# ENCODER0_REG_TOPAZHP_COREEXT_0 register map
Vendor: Texas Instruments
Peripheral module from a debugger description file (folder J7ES).
Registers are 32-bit, read-write, reset 0x0 unless marked. A register's access mark holds for its fields unless they carry their own. Offsets are as the file gives them; lines under a group give offsets from that group; [hi:lo] are bit positions; {n}, {i} and the like mark numbered series; 'fields as' and 'values as' point back to an identical list; <NAME> marks a mode.

## ENCODER0_REG_TOPAZHP_COREEXT_0
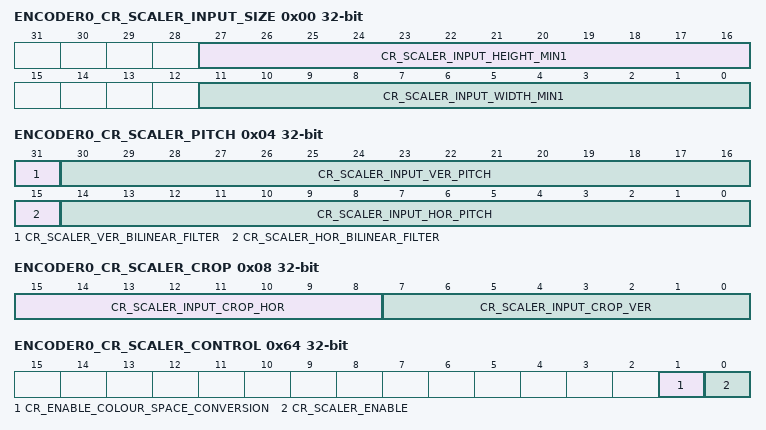
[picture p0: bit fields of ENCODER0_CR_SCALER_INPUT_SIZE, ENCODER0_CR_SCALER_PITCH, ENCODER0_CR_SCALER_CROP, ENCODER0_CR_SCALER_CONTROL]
0x00 ENCODER0_CR_SCALER_INPUT_SIZE access per field
  [27:16] CR_SCALER_INPUT_HEIGHT_MIN1 rw — Height in pixels of the in the input image to be scaled, minus 1
  [11:0] CR_SCALER_INPUT_WIDTH_MIN1 rw — Width in pixels of in the input image that is to be scaled, minus 1.
0x04 ENCODER0_CR_SCALER_PITCH
  [31] CR_SCALER_VER_BILINEAR_FILTER — When set the input image will be pre-processed using a bilinear filter to effectively half the image size in the vertical direction.
  [30:16] CR_SCALER_INPUT_VER_PITCH — Input Scaler vertical pitch:
  [15] CR_SCALER_HOR_BILINEAR_FILTER — When set the input image will be pre-processed using a bilinear filter to effectively half the image size in the horizontal direction.
  [14:0] CR_SCALER_INPUT_HOR_PITCH — Input Scaler horizontal pitch:
0x08 ENCODER0_CR_SCALER_CROP access per field
  [15:8] CR_SCALER_INPUT_CROP_HOR rw — Input_Scaler horizontal crop:
  [7:0] CR_SCALER_INPUT_CROP_VER rw — Input_Scaler vertical crop:
{0x10+4i} ENCODER0_CR_SCALER_VER_LUMA_COEFFS_{i:02} (i=0..3) — Coeffs for 1/16, 3/16, 5/16, 7/16These are mirrored internally to get 9/16, 11/16, 13/16 and 15/16 as well
  [31:24] CR_SCALER_VER_LUMA_COEFF — Vertical Luma coefficient for each of the 4 taps
{0x20+4i} ENCODER0_CR_SCALER_VER_CHROMA_COEFFS_{i:02} (i=0..3) — Coeffs for 1/16, 3/16, 5/16, 7/16These are mirrored internally to get 9/16, 11/16, 13/16 and 15/16 as well
  [31:24] CR_SCALER_VER_CHROMA_COEFF — Vertical Chroma coefficient for each of the 4 taps
{0x30+4i} ENCODER0_CR_SCALER_HOR_LUMA_COEFFS_{i:02} (i=0..3) — Coeffs for 1/16, 3/16, 5/16, 7/16These are mirrored internally to get 9/16, 11/16, 13/16 and 15/16 as well
  [31:24] CR_SCALER_HOR_LUMA_COEFF — Horizontal Luma coefficient for each of the 4 taps
{0x40+4i} ENCODER0_CR_SCALER_HOR_CHROMA_COEFFS_{i:02} (i=0..3) — Coeffs for 1/16, 3/16, 5/16, 7/16These are mirrored internally to get 9/16, 11/16, 13/16 and 15/16 as well\par
  [31:24] CR_SCALER_HOR_CHROMA_COEFF — Horizontal Chroma coefficient for each of the 4 taps
0x50 ENCODER0_CR_SCALER_MEM_BURST_REQ_CRC ro
  [31:0] CR_SCALER_MEM_BURST_REQ_CRC
0x54 ENCODER0_CR_SCALER_MEM_READ_DATA_CRC ro
  [31:0] CR_SCALER_MEM_READ_DATA_CRC
0x58 ENCODER0_CR_CURRENT_MB_DATA_CRC ro
  [31:0] CR_CURRENT_MB_DATA_CRC
0x5C ENCODER0_CR_HOR_BIFILTER_DATA_CRC ro
  [31:0] CR_HOR_BIFILTER_DATA_CRC
0x64 ENCODER0_CR_SCALER_CONTROL access per field — Scaler control
  [1] CR_ENABLE_COLOUR_SPACE_CONVERSION rw
  [0] CR_SCALER_ENABLE rw — Scaler enable flag: 0 scaler is disabled, 1 scaler is enabled.
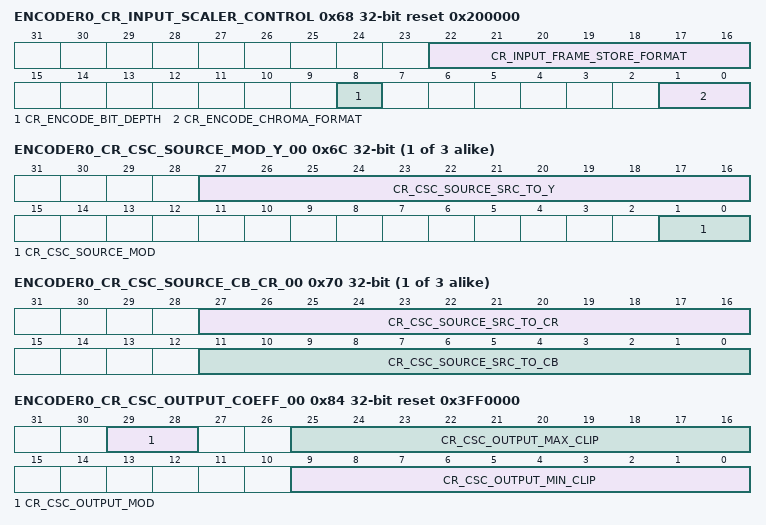
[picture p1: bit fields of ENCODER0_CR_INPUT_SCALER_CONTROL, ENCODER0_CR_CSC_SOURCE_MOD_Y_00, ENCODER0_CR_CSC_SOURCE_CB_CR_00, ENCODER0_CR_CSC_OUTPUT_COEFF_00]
0x68 ENCODER0_CR_INPUT_SCALER_CONTROL access per field reset 0x200000
  [22:16] CR_INPUT_FRAME_STORE_FORMAT rw — Input frame store format, where the bits
  [8] CR_ENCODE_BIT_DEPTH rw — Pixel component resolution to encode
  [1:0] CR_ENCODE_CHROMA_FORMAT rw — Chroma resolution of 'input scaler' output
{0x6C+8i} ENCODER0_CR_CSC_SOURCE_MOD_Y_{i:02} access per field (i=0..2) — For each of the source planes A, B and C, these fields define the contribution to the 3 output planes in the colour space conversion process.
  [27:16] CR_CSC_SOURCE_SRC_TO_Y rw — Scaling factor applied to modified source pixel component contributing to luma output plane [although colour space conversion may not be to YCbCr] [signed fixed point 2.10]
  [1:0] CR_CSC_SOURCE_MOD rw — This field defines any modification to source pixel component prior to scaling
{0x70+8i} ENCODER0_CR_CSC_SOURCE_CB_CR_{i:02} access per field (i=0..2) — For each of the source planes A, B and C, these fields define the contribution to the 3 output planes in the colour space conversion process.
  [27:16] CR_CSC_SOURCE_SRC_TO_CR rw — Scaling factor applied to modified source pixel component contributing to Cr output plane [although colour space conversion may not be to YCbCr] [signed fixed point 2.10]
  [11:0] CR_CSC_SOURCE_SRC_TO_CB rw — Scaling factor applied to modified source pixel component contributing to Cb output plane [although colour space conversion may not be to YCbCr] [signed fixed point 2.10]
0x84 ENCODER0_CR_CSC_OUTPUT_COEFF_00 access per field reset 0x3FF0000 — The first register defines the modification and clipping applied to the luma output plane, and the second register defines the modification and clipping applied to both the Cb and Cr output planes.
  [29:28] CR_CSC_OUTPUT_MOD rw — This field defines any modification to source pixel component prior to scaling
  [25:16] CR_CSC_OUTPUT_MAX_CLIP rw — Output from colour space conversion is clipped to this maximum value [in the case of
  [9:0] CR_CSC_OUTPUT_MIN_CLIP rw — Output from colour space conversion is clipped to this minimum value [in the case of
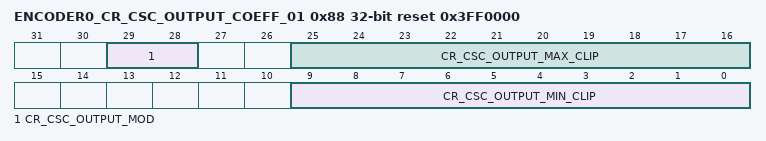
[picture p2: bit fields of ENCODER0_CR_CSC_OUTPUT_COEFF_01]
0x88 ENCODER0_CR_CSC_OUTPUT_COEFF_01 access per field reset 0x3FF0000 — The first register defines the modification and clipping applied to the luma output plane, and the second register defines the modification and clipping applied to both the Cb and Cr output planes.
  fields as ENCODER0_CR_CSC_OUTPUT_COEFF_00
0x90 ENCODER0_CR_SCALER_CSC_DATA_CRC ro
  [31:0] CR_SCALER_CSC_DATA_CRC — CRC signature of the colour space conversion output data
